VERSION ""

NS_ :

BS_:

BU_:

BO_ 3221225472 VECTOR__INDEPENDENT_SIG_MSG: 0 Vector__XXX
 SG_ Signal_23_Bit_Signed_M : 0|23@0- (1,0) [0|0] "" Vector__XXX
 SG_ Signal_23_Bit_Unsigned_M : 0|23@0+ (1,0) [0|0] "" Vector__XXX
 SG_ Signal_23_Bit_Unsigned_I : 0|23@1+ (1,0) [0|0] "" Vector__XXX
 SG_ Signal_23_Bit_Signed_I : 0|23@1- (1,0) [0|0] "" Vector__XXX

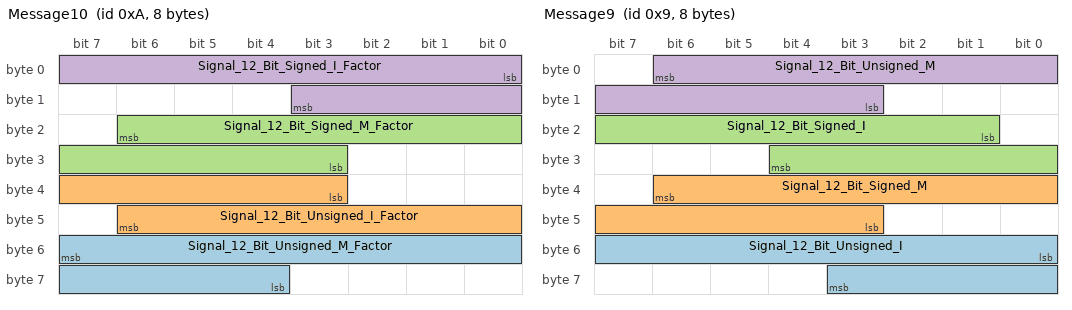
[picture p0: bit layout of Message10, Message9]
BO_ 10 Message10: 8 Vector__XXX
 SG_ Signal_12_Bit_Unsigned_M_Factor : 55|12@0+ (0.1,10) [0|0] "" Vector__XXX
 SG_ Signal_12_Bit_Unsigned_I_Factor : 35|12@1+ (0.1,10) [0|0] "" Vector__XXX
 SG_ Signal_12_Bit_Signed_M_Factor : 22|12@0- (0.1,10) [0|0] "" Vector__XXX
 SG_ Signal_12_Bit_Signed_I_Factor : 0|12@1- (0.1,10) [0|0] "" Vector__XXX

BO_ 9 Message9: 8 Vector__XXX
 SG_ Signal_12_Bit_Unsigned_I : 48|12@1+ (1,0) [0|0] "" Vector__XXX
 SG_ Signal_12_Bit_Signed_M : 38|12@0- (1,0) [0|0] "" Vector__XXX
 SG_ Signal_12_Bit_Signed_I : 17|12@1- (1,0) [0|0] "" Vector__XXX
 SG_ Signal_12_Bit_Unsigned_M : 6|12@0+ (1,0) [0|0] "" Vector__XXX

BO_ 8 Message8: 8 Vector__XXX
 SG_ Signal_64_Bit_Unsigned_I : 0|64@1+ (1,0) [0|0] "" Vector__XXX

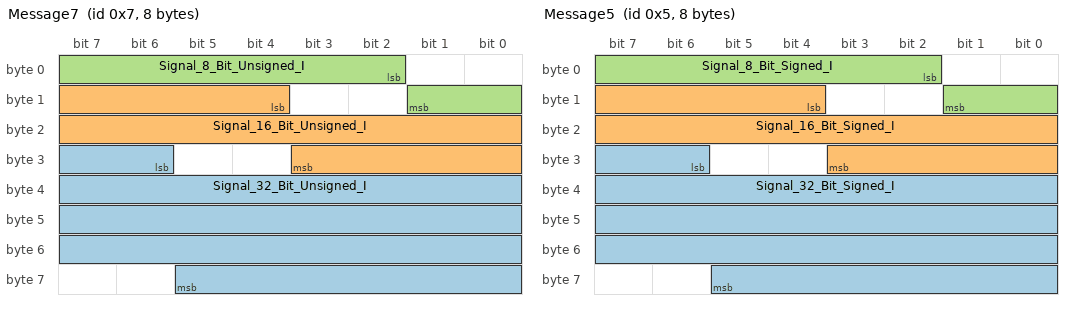
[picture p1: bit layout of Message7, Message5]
BO_ 7 Message7: 8 Vector__XXX
 SG_ Signal_32_Bit_Unsigned_I : 30|32@1+ (1,0) [0|0] "" Vector__XXX
 SG_ Signal_16_Bit_Unsigned_I : 12|16@1+ (1,0) [0|0] "" Vector__XXX
 SG_ Signal_8_Bit_Unsigned_I : 2|8@1+ (1,0) [0|0] "" Vector__XXX

BO_ 6 Message6: 8 Vector__XXX
 SG_ Signal_64_Bit_Signed_I : 0|64@1- (1,0) [0|0] "" Vector__XXX

BO_ 5 Message5: 8 Vector__XXX
 SG_ Signal_32_Bit_Signed_I : 30|32@1- (1,0) [0|0] "" Vector__XXX
 SG_ Signal_16_Bit_Signed_I : 12|16@1- (1,0) [0|0] "" Vector__XXX
 SG_ Signal_8_Bit_Signed_I : 2|8@1- (1,0) [0|0] "km/h" Vector__XXX

BO_ 4 Message4: 8 Vector__XXX
 SG_ Signal_64_Bit_Unsigned_M : 7|64@0+ (1,0) [0|0] "" Vector__XXX

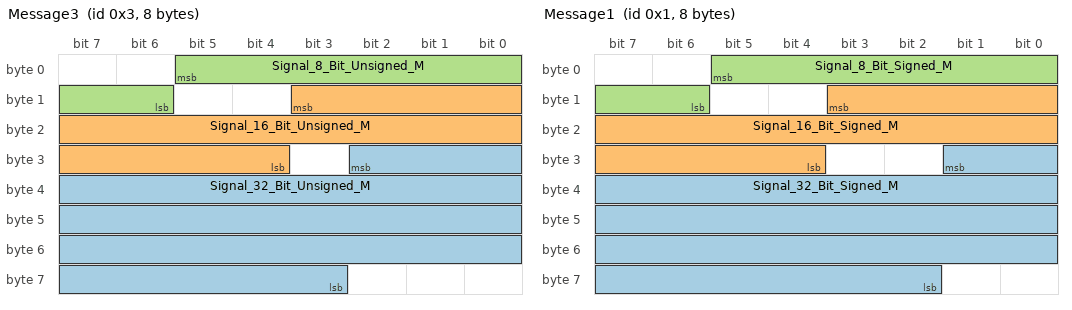
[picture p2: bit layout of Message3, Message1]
BO_ 3 Message3: 8 Vector__XXX
 SG_ Signal_32_Bit_Unsigned_M : 26|32@0+ (1,0) [0|0] "" Vector__XXX
 SG_ Signal_16_Bit_Unsigned_M : 11|16@0+ (1,0) [0|0] "" Vector__XXX
 SG_ Signal_8_Bit_Unsigned_M : 5|8@0+ (1,0) [0|0] "" Vector__XXX

BO_ 2 Message2: 8 Vector__XXX
 SG_ Signal_64_Bit_Signed_M : 7|64@0- (1,0) [0|0] "" Vector__XXX

BO_ 1 Message1: 8 Vector__XXX
 SG_ Signal_32_Bit_Signed_M : 25|32@0- (1,0) [0|0] "" Vector__XXX
 SG_ Signal_16_Bit_Signed_M : 11|16@0- (1,0) [0|0] "" Vector__XXX
 SG_ Signal_8_Bit_Signed_M : 5|8@0- (1,0) [0|0] "km/h" Vector__XXX

CM_ BO_ 3221225472 "This is a message for not used signals, created by Vector CANdb++ DBC OLE DB Provider.";
BA_DEF_  "BusType" STRING ;
BA_DEF_DEF_  "BusType" "CAN";
